# PIC32MX530F128H device description
Architecture: MIPS; Family: PIC32MX; Series: PIC32MX
Registers are 32-bit, read-write, no defined reset value unless marked. A register's access mark holds for its fields unless they carry their own. Offsets are from the block's base; [hi:lo] are bit positions; {n}, {i} and the like mark numbered series; 'fields as' and 'values as' point back to an identical list.

## FUSECONFIG
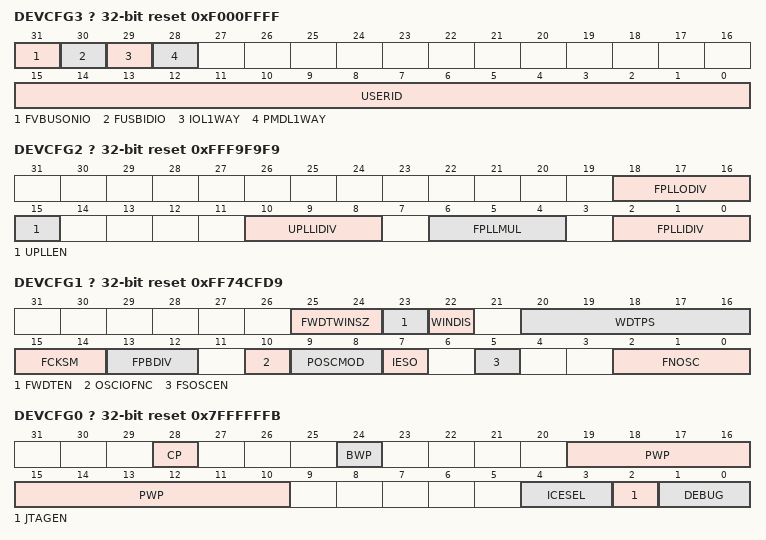
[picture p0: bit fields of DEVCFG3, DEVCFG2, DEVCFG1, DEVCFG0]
? DEVCFG3 size not given access not given reset 0xF000FFFF — Device Configuration Word 3
  [31] FVBUSONIO — USB VBUS_ON Selection bit
    1=ON (VBUSON pin is controlled by the USB module); 0=OFF (VBUSON pin is controlled by the port function)
  [30] FUSBIDIO — USB USBID Selection bit
    1=ON (USBID pin is controlled by the USB module); 0=OFF (USBID pin is controlled by the port function)
  [29] IOL1WAY — Peripheral Pin Select Configuration bit
    1=ON (Allow only one reconfiguration); 0=OFF (Allow multiple reconfigurations)
  [28] PMDL1WAY — Peripheral Module Disable Configuration bit
    values as IOL1WAY
  [15:0] USERID
    ?=User ID
? DEVCFG2 size not given access not given reset 0xFFF9F9F9 — Device Configuration Word 2
  [18:16] FPLLODIV — Default PLL Output Divisor bits
    7=DIV_256 (256x divider); 6=DIV_64 (64x divider); 5=DIV_32 (32x divider); 4=DIV_16 (16x divider); 3=DIV_8 (8x divider); 2=DIV_4 (4x divider); 1=DIV_2 (2x divider); 0=DIV_1 (1x divider)
  [15] UPLLEN — USB PLL Enable bit
    1=OFF (Disable and bypass USB PLL); 0=ON (Enable USB PLL)
  [10:8] UPLLIDIV — USB PLL Input Divider bits
    7=DIV_12 (12x divider); 6=DIV_10 (10x divider); {v}=DIV_{v+1} ({v+1}x divider) (v=0..5)
  [6:4] FPLLMUL — PLL Multiplier bits
    7=MUL_24 (24x multiplier); {v}=MUL_{v+15} ({v+15}x multiplier) (v=0..6)
  [2:0] FPLLIDIV — PLL Input Divider bits
    values as UPLLIDIV
? DEVCFG1 size not given access not given reset 0xFF74CFD9 — Device Configuration Word 1
  [25:24] FWDTWINSZ — Watchdog Timer Window Size bits
    3=WINSZ_25 (Window size is 25%); 2=WINSZ_37 (Window size is 37.5%); 1=WINSZ_50 (Window size is 50%); 0=WINSZ_75 (Window size is 75%)
  [23] FWDTEN — Watchdog Timer Enable bit
    0=OFF (Watchdog Timer is not enabled; it can be enabled in software); 1=ON (Watchdog Timer is enabled and cannot be disabled by software)
  [22] WINDIS — Watchdog Timer Window Enable bit
    1=OFF (Watchdog Timer is in non-Window mode); 0=ON (Watchdog Timer is in Window mode)
  [20:16] WDTPS — Watchdog Timer Postscale Select bits
    20=PS1048576 (1:1048576); 19=PS524288 (1:524288); 18=PS262144 (1:262144); 17=PS131072 (1:131072); 16=PS65536 (1:65536); 15=PS32768 (1:32768); 14=PS16384 (1:16384); 13=PS8192 (1:8192); 12=PS4096 (1:4096); 11=PS2048 (1:2048); 10=PS1024 (1:1024); 9=PS512 (1:512); 8=PS256 (1:256); 7=PS128 (1:128); 6=PS64 (1:64); 5=PS32 (1:32); 4=PS16 (1:16); 3=PS8 (1:8); 2=PS4 (1:4); 1=PS2 (1:2); 0=PS1 (1:1)
  [15:14] FCKSM — Clock Switching and Monitor Selection Configuration bits
    3=CSDCMD (Clock switching is disabled, Fail-Safe Clock Monitor is disabled); 1=CSECMD (Clock switching is enabled, Fail-Safe Clock Monitor is disabled); 0=CSECME (Clock switching is enabled, Fail-Safe Clock Monitor is enabled)
  [13:12] FPBDIV — Peripheral Bus Clock Divisor Default Value bits
    3=DIV_8 (PBCLK is SYSCLK divided by 8); 2=DIV_4 (PBCLK is SYSCLK divided by 4); 1=DIV_2 (PBCLK is SYSCLK divided by 2); 0=DIV_1 (PBCLK is SYSCLK divided by 1)
  [10] OSCIOFNC — CLKO Enable Configuration bit
    1=OFF (CLKO output is disabled); 0=ON (CLKO output signal active on the OSCO pin)
  [9:8] POSCMOD — Primary Oscillator Configuration bits
    3=OFF (Primary Oscillator disabled); 2=HS (HS Oscillator mode selected); 1=XT (XT Oscillator mode selected); 0=EC (External Clock mode selected)
  [7] IESO — Internal External Switchover bit
    0=OFF (Internal External Switchover mode is disabled (Two-Speed Start-up is disabled)); 1=ON (Internal External Switchover mode is enabled (Two-Speed Start-up is enabled))
  [5] FSOSCEN — Secondary Oscillator Enable bit
    0=OFF (Disable Secondary Oscillator); 1=ON (Enable Secondary Oscillator)
  [2:0] FNOSC — Oscillator Selection bits
    7=FRCDIV (Fast RC Oscillator with divide-by-N (FRCDIV)); 6=FRCDIV16 (FRCDIV16 Fast RC Oscillator with fixed divide-by-16 postscaler); 5=LPRC (Low-Power RC Oscillator (LPRC)); 4=SOSC (Secondary Oscillator (SOSC)); 3=PRIPLL (Primary Oscillator (POSC) with PLL module (XT+PLL, HS+PLL, EC+PLL)); 2=PRI (Primary Oscillator (XT, HS, EC)); 1=FRCPLL (Fast RC Oscillator with divide-by-N with PLL module (FRCDIV+PLL)); 0=FRC (Fast RC Oscillator (FRC))
? DEVCFG0 size not given access not given reset 0x7FFFFFFB — Device Configuration Word 0
  [28] CP — Code-Protect bit
    0=ON (Protection is enabled); 1=OFF (Protection is disabled)
  [24] BWP — Boot Flash Write-Protect bit
    1=OFF (Boot Flash is writable); 0=ON (Boot Flash is not writable)
  [19:10] PWP — Program Flash Write-Protect bits
    0x3ff=OFF (Disabled); 0x3fe=PWP1K (Memory below 0x400 address is write-protected); 0x3fd=PWP2K (Memory below 0x800 address is write-protected); 0x3fc=PWP3K (Memory below 0xC00 address is write-protected); 0x3fb=PWP4K (Memory below 0x1000 address is write-protected); 0x3fa=PWP5K (Memory below 0x1400 address is write-protected); 0x3f9=PWP6K (Memory below 0x1800 address is write-protected); 0x3f8=PWP7K (Memory below 0x1C00 address is write-protected); 0x3f7=PWP8K (Memory below 0x2000 address is write-protected); 0x3f6=PWP9K (Memory below 0x2400 address is write-protected); 0x3f5=PWP10K (Memory below 0x2800 address is write-protected); 0x3f4=PWP11K (Memory below 0x2C00 address is write-protected); 0x3f3=PWP12K (Memory below 0x3000 address is write-protected); 0x3f2=PWP13K (Memory below 0x3400 address is write-protected); 0x3f1=PWP14K (Memory below 0x3800 address is write-protected); 0x3f0=PWP15K (Memory below 0x3C00 address is write-protected); 0x3ef=PWP16K (Memory below 0x4000 address is write-protected); 0x3ee=PWP17K (Memory below 0x4400 address is write-protected); 0x3ed=PWP18K (Memory below 0x4800 address is write-protected); 0x3ec=PWP19K (Memory below 0x4C00 address is write-protected); 0x3eb=PWP20K (Memory below 0x5000 address is write-protected); 0x3ea=PWP21K (Memory below 0x5400 address is write-protected); 0x3e9=PWP22K (Memory below 0x5800 address is write-protected); 0x3e8=PWP23K (Memory below 0x5C00 address is write-protected); 0x3e7=PWP24K (Memory below 0x6000 address is write-protected); 0x3e6=PWP25K (Memory below 0x6400 address is write-protected); 0x3e5=PWP26K (Memory below 0x6800 address is write-protected); 0x3e4=PWP27K (Memory below 0x6C00 address is write-protected); 0x3e3=PWP28K (Memory below 0x7000 address is write-protected); 0x3e2=PWP29K (Memory below 0x7400 address is write-protected); 0x3e1=PWP30K (Memory below 0x7800 address is write-protected); 0x3e0=PWP31K (Memory below 0x7C00 address is write-protected); 0x3df=PWP32K (Memory below 0x8000 address is write-protected); 0x3de=PWP33K (Memory below 0x8400 address is write-protected); 0x3dd=PWP34K (Memory below 0x8800 address is write-protected); 0x3dc=PWP35K (Memory below 0x8C00 address is write-protected); 0x3db=PWP36K (Memory below 0x9000 address is write-protected); 0x3da=PWP37K (Memory below 0x9400 address is write-protected); 0x3d9=PWP38K (Memory below 0x9800 address is write-protected); 0x3d8=PWP39K (Memory below 0x9C00 address is write-protected); 0x3d7=PWP40K (Memory below 0xA000 address is write-protected); 0x3d6=PWP41K (Memory below 0xA400 address is write-protected); 0x3d5=PWP42K (Memory below 0xA800 address is write-protected); 0x3d4=PWP43K (Memory below 0xAC00 address is write-protected); 0x3d3=PWP44K (Memory below 0xB000 address is write-protected); 0x3d2=PWP45K (Memory below 0xB400 address is write-protected); 0x3d1=PWP46K (Memory below 0xB800 address is write-protected); 0x3d0=PWP47K (Memory below 0xBC00 address is write-protected); 0x3cf=PWP48K (Memory below 0xC000 address is write-protected); 0x3ce=PWP49K (Memory below 0xC400 address is write-protected); 0x3cd=PWP50K (Memory below 0xC800 address is write-protected); 0x3cc=PWP51K (Memory below 0xCC00 address is write-protected); 0x3cb=PWP52K (Memory below 0xD000 address is write-protected); 0x3ca=PWP53K (Memory below 0xD400 address is write-protected); 0x3c9=PWP54K (Memory below 0xD800 address is write-protected); 0x3c8=PWP55K (Memory below 0xDC00 address is write-protected); 0x3c7=PWP56K (Memory below 0xE000 address is write-protected); 0x3c6=PWP57K (Memory below 0xE400 address is write-protected); 0x3c5=PWP58K (Memory below 0xE800 address is write-protected); 0x3c4=PWP59K (Memory below 0xEC00 address is write-protected); 0x3c3=PWP60K (Memory below 0xF000 address is write-protected); 0x3c2=PWP61K (Memory below 0xF400 address is write-protected); 0x3c1=PWP62K (Memory below 0xF800 address is write-protected); 0x3c0=PWP63K (Memory below 0xFC00 address is write-protected); 0x3bf=PWP64K (Memory below 0x10000 address is write-protected); 0x3be=PWP65K (Memory below 0x10400 address is write-protected); 0x3bd=PWP66K (Memory below 0x10800 address is write-protected); 0x3bc=PWP67K (Memory below 0x10C00 address is write-protected); 0x3bb=PWP68K (Memory below 0x11000 address is write-protected); 0x3ba=PWP69K (Memory below 0x11400 address is write-protected); 0x3b9=PWP70K (Memory below 0x11800 address is write-protected); 0x3b8=PWP71K (Memory below 0x11C00 address is write-protected); 0x3b7=PWP72K (Memory below 0x12000 address is write-protected); 0x3b6=PWP73K (Memory below 0x12400 address is write-protected); 0x3b5=PWP74K (Memory below 0x12800 address is write-protected); 0x3b4=PWP75K (Memory below 0x12C00 address is write-protected); 0x3b3=PWP76K (Memory below 0x13000 address is write-protected); 0x3b2=PWP77K (Memory below 0x13400 address is write-protected); 0x3b1=PWP78K (Memory below 0x13800 address is write-protected); 0x3b0=PWP79K (Memory below 0x13C00 address is write-protected); 0x3af=PWP80K (Memory below 0x14000 address is write-protected); 0x3ae=PWP81K (Memory below 0x14400 address is write-protected); 0x3ad=PWP82K (Memory below 0x14800 address is write-protected); 0x3ac=PWP83K (Memory below 0x14C00 address is write-protected); 0x3ab=PWP84K (Memory below 0x15000 address is write-protected); 0x3aa=PWP85K (Memory below 0x15400 address is write-protected); 0x3a9=PWP86K (Memory below 0x15800 address is write-protected); 0x3a8=PWP87K (Memory below 0x15C00 address is write-protected); 0x3a7=PWP88K (Memory below 0x16000 address is write-protected); 0x3a6=PWP89K (Memory below 0x16400 address is write-protected); 0x3a5=PWP90K (Memory below 0x16800 address is write-protected); 0x3a4=PWP91K (Memory below 0x16C00 address is write-protected); 0x3a3=PWP92K (Memory below 0x17000 address is write-protected); 0x3a2=PWP93K (Memory below 0x17400 address is write-protected); 0x3a1=PWP94K (Memory below 0x17800 address is write-protected); 0x3a0=PWP95K (Memory below 0x17C00 address is write-protected); 0x39f=PWP96K (Memory below 0x18000 address is write-protected); 0x39e=PWP97K (Memory below 0x18400 address is write-protected); 0x39d=PWP98K (Memory below 0x18800 address is write-protected); 0x39c=PWP99K (Memory below 0x18C00 address is write-protected); 0x39b=PWP100K (Memory below 0x19000 address is write-protected); 0x39a=PWP101K (Memory below 0x19400 address is write-protected); 0x399=PWP102K (Memory below 0x19800 address is write-protected); 0x398=PWP103K (Memory below 0x19C00 address is write-protected); 0x397=PWP104K (Memory below 0x1A000 address is write-protected); 0x396=PWP105K (Memory below 0x1A400 address is write-protected); 0x395=PWP106K (Memory below 0x1A800 address is write-protected); 0x394=PWP107K (Memory below 0x1AC00 address is write-protected); 0x393=PWP108K (Memory below 0x1B000 address is write-protected); 0x392=PWP109K (Memory below 0x1B400 address is write-protected); 0x391=PWP110K (Memory below 0x1B800 address is write-protected); 0x390=PWP111K (Memory below 0x1BC00 address is write-protected); 0x38f=PWP112K (Memory below 0x1C000 address is write-protected); 0x38e=PWP113K (Memory below 0x1C400 address is write-protected); 0x38d=PWP114K (Memory below 0x1C800 address is write-protected); 0x38c=PWP115K (Memory below 0x1CC00 address is write-protected); 0x38b=PWP116K (Memory below 0x1D000 address is write-protected); 0x38a=PWP117K (Memory below 0x1D400 address is write-protected); 0x389=PWP118K (Memory below 0x1D800 address is write-protected); 0x388=PWP119K (Memory below 0x1DC00 address is write-protected); 0x387=PWP120K (Memory below 0x1E000 address is write-protected); 0x386=PWP121K (Memory below 0x1E400 address is write-protected); 0x385=PWP122K (Memory below 0x1E800 address is write-protected); 0x384=PWP123K (Memory below 0x1EC00 address is write-protected); 0x383=PWP124K (Memory below 0x1F000 address is write-protected); 0x382=PWP125K (Memory below 0x1F400 address is write-protected); 0x381=PWP126K (Memory below 0x1F800 address is write-protected); 0x380=PWP127K (Memory below 0x1FC00 address is write-protected); 0x37f=PWP128K (Memory below 0x20000 address is write-protected); 0x37e=PWP129K (Memory below 0x20400 address is write-protected); 0x37d=PWP130K (Memory below 0x20800 address is write-protected); 0x37c=PWP131K (Memory below 0x20C00 address is write-protected); 0x37b=PWP132K (Memory below 0x21000 address is write-protected); 0x37a=PWP133K (Memory below 0x21400 address is write-protected); 0x379=PWP134K (Memory below 0x21800 address is write-protected); 0x378=PWP135K (Memory below 0x21C00 address is write-protected); 0x377=PWP136K (Memory below 0x22000 address is write-protected); 0x376=PWP137K (Memory below 0x22400 address is write-protected); 0x375=PWP138K (Memory below 0x22800 address is write-protected); 0x374=PWP139K (Memory below 0x22C00 address is write-protected); 0x373=PWP140K (Memory below 0x23000 address is write-protected); 0x372=PWP141K (Memory below 0x23400 address is write-protected); 0x371=PWP142K (Memory below 0x23800 address is write-protected); 0x370=PWP143K (Memory below 0x23C00 address is write-protected); 0x36f=PWP144K (Memory below 0x24000 address is write-protected); 0x36e=PWP145K (Memory below 0x24400 address is write-protected); 0x36d=PWP146K (Memory below 0x24800 address is write-protected); 0x36c=PWP147K (Memory below 0x24C00 address is write-protected); 0x36b=PWP148K (Memory below 0x25000 address is write-protected); 0x36a=PWP149K (Memory below 0x25400 address is write-protected); 0x369=PWP150K (Memory below 0x25800 address is write-protected); 0x368=PWP151K (Memory below 0x25C00 address is write-protected); 0x367=PWP152K (Memory below 0x26000 address is write-protected); 0x366=PWP153K (Memory below 0x26400 address is write-protected); 0x365=PWP154K (Memory below 0x26800 address is write-protected); 0x364=PWP155K (Memory below 0x26C00 address is write-protected); 0x363=PWP156K (Memory below 0x27000 address is write-protected); 0x362=PWP157K (Memory below 0x27400 address is write-protected); 0x361=PWP158K (Memory below 0x27800 address is write-protected); 0x360=PWP159K (Memory below 0x27C00 address is write-protected); 0x35f=PWP160K (Memory below 0x28000 address is write-protected); 0x35e=PWP161K (Memory below 0x28400 address is write-protected); 0x35d=PWP162K (Memory below 0x28800 address is write-protected); 0x35c=PWP163K (Memory below 0x28C00 address is write-protected); 0x35b=PWP164K (Memory below 0x29000 address is write-protected); 0x35a=PWP165K (Memory below 0x29400 address is write-protected); 0x359=PWP166K (Memory below 0x29800 address is write-protected); 0x358=PWP167K (Memory below 0x29C00 address is write-protected); 0x357=PWP168K (Memory below 0x2A000 address is write-protected); 0x356=PWP169K (Memory below 0x2A400 address is write-protected); 0x355=PWP170K (Memory below 0x2A800 address is write-protected); 0x354=PWP171K (Memory below 0x2AC00 address is write-protected); 0x353=PWP172K (Memory below 0x2B000 address is write-protected); 0x352=PWP173K (Memory below 0x2B400 address is write-protected); 0x351=PWP174K (Memory below 0x2B800 address is write-protected); 0x350=PWP175K (Memory below 0x2BC00 address is write-protected); 0x34f=PWP176K (Memory below 0x2C000 address is write-protected); 0x34e=PWP177K (Memory below 0x2C400 address is write-protected); 0x34d=PWP178K (Memory below 0x2C800 address is write-protected); 0x34c=PWP179K (Memory below 0x2CC00 address is write-protected); 0x34b=PWP180K (Memory below 0x2D000 address is write-protected); 0x34a=PWP181K (Memory below 0x2D400 address is write-protected); 0x349=PWP182K (Memory below 0x2D800 address is write-protected); 0x348=PWP183K (Memory below 0x2DC00 address is write-protected); 0x347=PWP184K (Memory below 0x2E000 address is write-protected); 0x346=PWP185K (Memory below 0x2E400 address is write-protected); 0x345=PWP186K (Memory below 0x2E800 address is write-protected); 0x344=PWP187K (Memory below 0x2EC00 address is write-protected); 0x343=PWP188K (Memory below 0x2F000 address is write-protected); 0x342=PWP189K (Memory below 0x2F400 address is write-protected); 0x341=PWP190K (Memory below 0x2F800 address is write-protected); 0x340=PWP191K (Memory below 0x2FC00 address is write-protected); 0x33f=PWP192K (Memory below 0x30000 address is write-protected); 0x33e=PWP193K (Memory below 0x30400 address is write-protected); 0x33d=PWP194K (Memory below 0x30800 address is write-protected); 0x33c=PWP195K (Memory below 0x30C00 address is write-protected); 0x33b=PWP196K (Memory below 0x31000 address is write-protected); 0x33a=PWP197K (Memory below 0x31400 address is write-protected); 0x339=PWP198K (Memory below 0x31800 address is write-protected); 0x338=PWP199K (Memory below 0x31C00 address is write-protected); 0x337=PWP200K (Memory below 0x32000 address is write-protected); 0x336=PWP201K (Memory below 0x32400 address is write-protected); 0x335=PWP202K (Memory below 0x32800 address is write-protected); 0x334=PWP203K (Memory below 0x32C00 address is write-protected); 0x333=PWP204K (Memory below 0x33000 address is write-protected); 0x332=PWP205K (Memory below 0x33400 address is write-protected); 0x331=PWP206K (Memory below 0x33800 address is write-protected); 0x330=PWP207K (Memory below 0x33C00 address is write-protected); 0x32f=PWP208K (Memory below 0x34000 address is write-protected); 0x32e=PWP209K (Memory below 0x34400 address is write-protected); 0x32d=PWP210K (Memory below 0x34800 address is write-protected); 0x32c=PWP211K (Memory below 0x34C00 address is write-protected); 0x32b=PWP212K (Memory below 0x35000 address is write-protected); 0x32a=PWP213K (Memory below 0x35400 address is write-protected); 0x329=PWP214K (Memory below 0x35800 address is write-protected); 0x328=PWP215K (Memory below 0x35C00 address is write-protected); 0x327=PWP216K (Memory below 0x36000 address is write-protected); 0x326=PWP217K (Memory below 0x36400 address is write-protected); 0x325=PWP218K (Memory below 0x36800 address is write-protected); 0x324=PWP219K (Memory below 0x36C00 address is write-protected); 0x323=PWP220K (Memory below 0x37000 address is write-protected); 0x322=PWP221K (Memory below 0x37400 address is write-protected); 0x321=PWP222K (Memory below 0x37800 address is write-protected); 0x320=PWP223K (Memory below 0x37C00 address is write-protected); 0x31f=PWP224K (Memory below 0x38000 address is write-protected); 0x31e=PWP225K (Memory below 0x38400 address is write-protected); 0x31d=PWP226K (Memory below 0x38800 address is write-protected); 0x31c=PWP227K (Memory below 0x38C00 address is write-protected); 0x31b=PWP228K (Memory below 0x39000 address is write-protected); 0x31a=PWP229K (Memory below 0x39400 address is write-protected); 0x319=PWP230K (Memory below 0x39800 address is write-protected); 0x318=PWP231K (Memory below 0x39C00 address is write-protected); 0x317=PWP232K (Memory below 0x3A000 address is write-protected); 0x316=PWP233K (Memory below 0x3A400 address is write-protected); 0x315=PWP234K (Memory below 0x3A800 address is write-protected); 0x314=PWP235K (Memory below 0x3AC00 address is write-protected); 0x313=PWP236K (Memory below 0x3B000 address is write-protected); 0x312=PWP237K (Memory below 0x3B400 address is write-protected); 0x311=PWP238K (Memory below 0x3B800 address is write-protected); 0x310=PWP239K (Memory below 0x3BC00 address is write-protected); 0x30f=PWP240K (Memory below 0x3C000 address is write-protected); 0x30e=PWP241K (Memory below 0x3C400 address is write-protected); 0x30d=PWP242K (Memory below 0x3C800 address is write-protected); 0x30c=PWP243K (Memory below 0x3CC00 address is write-protected); 0x30b=PWP244K (Memory below 0x3D000 address is write-protected); 0x30a=PWP245K (Memory below 0x3D400 address is write-protected); 0x309=PWP246K (Memory below 0x3D800 address is write-protected); 0x308=PWP247K (Memory below 0x3DC00 address is write-protected); 0x307=PWP248K (Memory below 0x3E000 address is write-protected); 0x306=PWP249K (Memory below 0x3E400 address is write-protected); 0x305=PWP250K (Memory below 0x3E800 address is write-protected); 0x304=PWP251K (Memory below 0x3EC00 address is write-protected); 0x303=PWP252K (Memory below 0x3F000 address is write-protected); 0x302=PWP253K (Memory below 0x3F400 address is write-protected); 0x301=PWP254K (Memory below 0x3F800 address is write-protected); 0x300=PWP255K (Memory below 0x3FC00 address is write-protected); 0x2ff=PWP256K (Memory below 0x40000 address is write-protected); 0x2fe=PWP257K (Memory below 0x40400 address is write-protected); 0x2fd=PWP258K (Memory below 0x40800 address is write-protected); 0x2fc=PWP259K (Memory below 0x40C00 address is write-protected); 0x2fb=PWP260K (Memory below 0x41000 address is write-protected); 0x2fa=PWP261K (Memory below 0x41400 address is write-protected); 0x2f9=PWP262K (Memory below 0x41800 address is write-protected); 0x2f8=PWP263K (Memory below 0x41C00 address is write-protected); 0x2f7=PWP264K (Memory below 0x42000 address is write-protected); 0x2f6=PWP265K (Memory below 0x42400 address is write-protected); 0x2f5=PWP266K (Memory below 0x42800 address is write-protected); 0x2f4=PWP267K (Memory below 0x42C00 address is write-protected); 0x2f3=PWP268K (Memory below 0x43000 address is write-protected); 0x2f2=PWP269K (Memory below 0x43400 address is write-protected); 0x2f1=PWP270K (Memory below 0x43800 address is write-protected); 0x2f0=PWP271K (Memory below 0x43C00 address is write-protected); 0x2ef=PWP272K (Memory below 0x44000 address is write-protected); 0x2ee=PWP273K (Memory below 0x44400 address is write-protected); 0x2ed=PWP274K (Memory below 0x44800 address is write-protected); 0x2ec=PWP275K (Memory below 0x44C00 address is write-protected); 0x2eb=PWP276K (Memory below 0x45000 address is write-protected); 0x2ea=PWP277K (Memory below 0x45400 address is write-protected); 0x2e9=PWP278K (Memory below 0x45800 address is write-protected); 0x2e8=PWP279K (Memory below 0x45C00 address is write-protected); 0x2e7=PWP280K (Memory below 0x46000 address is write-protected); 0x2e6=PWP281K (Memory below 0x46400 address is write-protected); 0x2e5=PWP282K (Memory below 0x46800 address is write-protected); 0x2e4=PWP283K (Memory below 0x46C00 address is write-protected); 0x2e3=PWP284K (Memory below 0x47000 address is write-protected); 0x2e2=PWP285K (Memory below 0x47400 address is write-protected); 0x2e1=PWP286K (Memory below 0x47800 address is write-protected); 0x2e0=PWP287K (Memory below 0x47C00 address is write-protected); 0x2df=PWP288K (Memory below 0x48000 address is write-protected); 0x2de=PWP289K (Memory below 0x48400 address is write-protected); 0x2dd=PWP290K (Memory below 0x48800 address is write-protected); 0x2dc=PWP291K (Memory below 0x48C00 address is write-protected); 0x2db=PWP292K (Memory below 0x49000 address is write-protected); 0x2da=PWP293K (Memory below 0x49400 address is write-protected); 0x2d9=PWP294K (Memory below 0x49800 address is write-protected); 0x2d8=PWP295K (Memory below 0x49C00 address is write-protected); 0x2d7=PWP296K (Memory below 0x4A000 address is write-protected); 0x2d6=PWP297K (Memory below 0x4A400 address is write-protected); 0x2d5=PWP298K (Memory below 0x4A800 address is write-protected); 0x2d4=PWP299K (Memory below 0x4AC00 address is write-protected); 0x2d3=PWP300K (Memory below 0x4B000 address is write-protected); 0x2d2=PWP301K (Memory below 0x4B400 address is write-protected); 0x2d1=PWP302K (Memory below 0x4B800 address is write-protected); 0x2d0=PWP303K (Memory below 0x4BC00 address is write-protected); 0x2cf=PWP304K (Memory below 0x4C000 address is write-protected); 0x2ce=PWP305K (Memory below 0x4C400 address is write-protected); 0x2cd=PWP306K (Memory below 0x4C800 address is write-protected); 0x2cc=PWP307K (Memory below 0x4CC00 address is write-protected); 0x2cb=PWP308K (Memory below 0x4D000 address is write-protected); 0x2ca=PWP309K (Memory below 0x4D400 address is write-protected); 0x2c9=PWP310K (Memory below 0x4D800 address is write-protected); 0x2c8=PWP311K (Memory below 0x4DC00 address is write-protected); 0x2c7=PWP312K (Memory below 0x4E000 address is write-protected); 0x2c6=PWP313K (Memory below 0x4E400 address is write-protected); 0x2c5=PWP314K (Memory below 0x4E800 address is write-protected); 0x2c4=PWP315K (Memory below 0x4EC00 address is write-protected); 0x2c3=PWP316K (Memory below 0x4F000 address is write-protected); 0x2c2=PWP317K (Memory below 0x4F400 address is write-protected); 0x2c1=PWP318K (Memory below 0x4F800 address is write-protected); 0x2c0=PWP319K (Memory below 0x4FC00 address is write-protected); 0x2bf=PWP320K (Memory below 0x50000 address is write-protected); 0x2be=PWP321K (Memory below 0x50400 address is write-protected); 0x2bd=PWP322K (Memory below 0x50800 address is write-protected); 0x2bc=PWP323K (Memory below 0x50C00 address is write-protected); 0x2bb=PWP324K (Memory below 0x51000 address is write-protected); 0x2ba=PWP325K (Memory below 0x51400 address is write-protected); 0x2b9=PWP326K (Memory below 0x51800 address is write-protected); 0x2b8=PWP327K (Memory below 0x51C00 address is write-protected); 0x2b7=PWP328K (Memory below 0x52000 address is write-protected); 0x2b6=PWP329K (Memory below 0x52400 address is write-protected); 0x2b5=PWP330K (Memory below 0x52800 address is write-protected); 0x2b4=PWP331K (Memory below 0x52C00 address is write-protected); 0x2b3=PWP332K (Memory below 0x53000 address is write-protected); 0x2b2=PWP333K (Memory below 0x53400 address is write-protected); 0x2b1=PWP334K (Memory below 0x53800 address is write-protected); 0x2b0=PWP335K (Memory below 0x53C00 address is write-protected); 0x2af=PWP336K (Memory below 0x54000 address is write-protected); 0x2ae=PWP337K (Memory below 0x54400 address is write-protected); 0x2ad=PWP338K (Memory below 0x54800 address is write-protected); 0x2ac=PWP339K (Memory below 0x54C00 address is write-protected); 0x2ab=PWP340K (Memory below 0x55000 address is write-protected); 0x2aa=PWP341K (Memory below 0x55400 address is write-protected); 0x2a9=PWP342K (Memory below 0x55800 address is write-protected); 0x2a8=PWP343K (Memory below 0x55C00 address is write-protected); 0x2a7=PWP344K (Memory below 0x56000 address is write-protected); 0x2a6=PWP345K (Memory below 0x56400 address is write-protected); 0x2a5=PWP346K (Memory below 0x56800 address is write-protected); 0x2a4=PWP347K (Memory below 0x56C00 address is write-protected); 0x2a3=PWP348K (Memory below 0x57000 address is write-protected); 0x2a2=PWP349K (Memory below 0x57400 address is write-protected); 0x2a1=PWP350K (Memory below 0x57800 address is write-protected); 0x2a0=PWP351K (Memory below 0x57C00 address is write-protected); 0x29f=PWP352K (Memory below 0x58000 address is write-protected); 0x29e=PWP353K (Memory below 0x58400 address is write-protected); 0x29d=PWP354K (Memory below 0x58800 address is write-protected); 0x29c=PWP355K (Memory below 0x58C00 address is write-protected); 0x29b=PWP356K (Memory below 0x59000 address is write-protected); 0x29a=PWP357K (Memory below 0x59400 address is write-protected); 0x299=PWP358K (Memory below 0x59800 address is write-protected); 0x298=PWP359K (Memory below 0x59C00 address is write-protected); 0x297=PWP360K (Memory below 0x5A000 address is write-protected); 0x296=PWP361K (Memory below 0x5A400 address is write-protected); 0x295=PWP362K (Memory below 0x5A800 address is write-protected); 0x294=PWP363K (Memory below 0x5AC00 address is write-protected); 0x293=PWP364K (Memory below 0x5B000 address is write-protected); 0x292=PWP365K (Memory below 0x5B400 address is write-protected); 0x291=PWP366K (Memory below 0x5B800 address is write-protected); 0x290=PWP367K (Memory below 0x5BC00 address is write-protected); 0x28f=PWP368K (Memory below 0x5C000 address is write-protected); 0x28e=PWP369K (Memory below 0x5C400 address is write-protected); 0x28d=PWP370K (Memory below 0x5C800 address is write-protected); 0x28c=PWP371K (Memory below 0x5CC00 address is write-protected); 0x28b=PWP372K (Memory below 0x5D000 address is write-protected); 0x28a=PWP373K (Memory below 0x5D400 address is write-protected); 0x289=PWP374K (Memory below 0x5D800 address is write-protected); 0x288=PWP375K (Memory below 0x5DC00 address is write-protected); 0x287=PWP376K (Memory below 0x5E000 address is write-protected); 0x286=PWP377K (Memory below 0x5E400 address is write-protected); 0x285=PWP378K (Memory below 0x5E800 address is write-protected); 0x284=PWP379K (Memory below 0x5EC00 address is write-protected); 0x283=PWP380K (Memory below 0x5F000 address is write-protected); 0x282=PWP381K (Memory below 0x5F400 address is write-protected); 0x281=PWP382K (Memory below 0x5F800 address is write-protected); 0x280=PWP383K (Memory below 0x5FC00 address is write-protected); 0x27f=PWP384K (Memory below 0x60000 address is write-protected); 0x27e=PWP385K (Memory below 0x60400 address is write-protected); 0x27d=PWP386K (Memory below 0x60800 address is write-protected); 0x27c=PWP387K (Memory below 0x60C00 address is write-protected); 0x27b=PWP388K (Memory below 0x61000 address is write-protected); 0x27a=PWP389K (Memory below 0x61400 address is write-protected); 0x279=PWP390K (Memory below 0x61800 address is write-protected); 0x278=PWP391K (Memory below 0x61C00 address is write-protected); 0x277=PWP392K (Memory below 0x62000 address is write-protected); 0x276=PWP393K (Memory below 0x62400 address is write-protected); 0x275=PWP394K (Memory below 0x62800 address is write-protected); 0x274=PWP395K (Memory below 0x62C00 address is write-protected); 0x273=PWP396K (Memory below 0x63000 address is write-protected); 0x272=PWP397K (Memory below 0x63400 address is write-protected); 0x271=PWP398K (Memory below 0x63800 address is write-protected); 0x270=PWP399K (Memory below 0x63C00 address is write-protected); 0x26f=PWP400K (Memory below 0x64000 address is write-protected); 0x26e=PWP401K (Memory below 0x64400 address is write-protected); 0x26d=PWP402K (Memory below 0x64800 address is write-protected); 0x26c=PWP403K (Memory below 0x64C00 address is write-protected); 0x26b=PWP404K (Memory below 0x65000 address is write-protected); 0x26a=PWP405K (Memory below 0x65400 address is write-protected); 0x269=PWP406K (Memory below 0x65800 address is write-protected); 0x268=PWP407K (Memory below 0x65C00 address is write-protected); 0x267=PWP408K (Memory below 0x66000 address is write-protected); 0x266=PWP409K (Memory below 0x66400 address is write-protected); 0x265=PWP410K (Memory below 0x66800 address is write-protected); 0x264=PWP411K (Memory below 0x66C00 address is write-protected); 0x263=PWP412K (Memory below 0x67000 address is write-protected); 0x262=PWP413K (Memory below 0x67400 address is write-protected); 0x261=PWP414K (Memory below 0x67800 address is write-protected); 0x260=PWP415K (Memory below 0x67C00 address is write-protected); 0x25f=PWP416K (Memory below 0x68000 address is write-protected); 0x25e=PWP417K (Memory below 0x68400 address is write-protected); 0x25d=PWP418K (Memory below 0x68800 address is write-protected); 0x25c=PWP419K (Memory below 0x68C00 address is write-protected); 0x25b=PWP420K (Memory below 0x69000 address is write-protected); 0x25a=PWP421K (Memory below 0x69400 address is write-protected); 0x259=PWP422K (Memory below 0x69800 address is write-protected); 0x258=PWP423K (Memory below 0x69C00 address is write-protected); 0x257=PWP424K (Memory below 0x6A000 address is write-protected); 0x256=PWP425K (Memory below 0x6A400 address is write-protected); 0x255=PWP426K (Memory below 0x6A800 address is write-protected); 0x254=PWP427K (Memory below 0x6AC00 address is write-protected); 0x253=PWP428K (Memory below 0x6B000 address is write-protected); 0x252=PWP429K (Memory below 0x6B400 address is write-protected); 0x251=PWP430K (Memory below 0x6B800 address is write-protected); 0x250=PWP431K (Memory below 0x6BC00 address is write-protected); 0x24f=PWP432K (Memory below 0x6C000 address is write-protected); 0x24e=PWP433K (Memory below 0x6C400 address is write-protected); 0x24d=PWP434K (Memory below 0x6C800 address is write-protected); 0x24c=PWP435K (Memory below 0x6CC00 address is write-protected); 0x24b=PWP436K (Memory below 0x6D000 address is write-protected); 0x24a=PWP437K (Memory below 0x6D400 address is write-protected); 0x249=PWP438K (Memory below 0x6D800 address is write-protected); 0x248=PWP439K (Memory below 0x6DC00 address is write-protected); 0x247=PWP440K (Memory below 0x6E000 address is write-protected); 0x246=PWP441K (Memory below 0x6E400 address is write-protected); 0x245=PWP442K (Memory below 0x6E800 address is write-protected); 0x244=PWP443K (Memory below 0x6EC00 address is write-protected); 0x243=PWP444K (Memory below 0x6F000 address is write-protected); 0x242=PWP445K (Memory below 0x6F400 address is write-protected); 0x241=PWP446K (Memory below 0x6F800 address is write-protected); 0x240=PWP447K (Memory below 0x6FC00 address is write-protected); 0x23f=PWP448K (Memory below 0x70000 address is write-protected); 0x23e=PWP449K (Memory below 0x70400 address is write-protected); 0x23d=PWP450K (Memory below 0x70800 address is write-protected); 0x23c=PWP451K (Memory below 0x70C00 address is write-protected); 0x23b=PWP452K (Memory below 0x71000 address is write-protected); 0x23a=PWP453K (Memory below 0x71400 address is write-protected); 0x239=PWP454K (Memory below 0x71800 address is write-protected); 0x238=PWP455K (Memory below 0x71C00 address is write-protected); 0x237=PWP456K (Memory below 0x72000 address is write-protected); 0x236=PWP457K (Memory below 0x72400 address is write-protected); 0x235=PWP458K (Memory below 0x72800 address is write-protected); 0x234=PWP459K (Memory below 0x72C00 address is write-protected); 0x233=PWP460K (Memory below 0x73000 address is write-protected); 0x232=PWP461K (Memory below 0x73400 address is write-protected); 0x231=PWP462K (Memory below 0x73800 address is write-protected); 0x230=PWP463K (Memory below 0x73C00 address is write-protected); 0x22f=PWP464K (Memory below 0x74000 address is write-protected); 0x22e=PWP465K (Memory below 0x74400 address is write-protected); 0x22d=PWP466K (Memory below 0x74800 address is write-protected); 0x22c=PWP467K (Memory below 0x74C00 address is write-protected); 0x22b=PWP468K (Memory below 0x75000 address is write-protected); 0x22a=PWP469K (Memory below 0x75400 address is write-protected); 0x229=PWP470K (Memory below 0x75800 address is write-protected); 0x228=PWP471K (Memory below 0x75C00 address is write-protected); 0x227=PWP472K (Memory below 0x76000 address is write-protected); 0x226=PWP473K (Memory below 0x76400 address is write-protected); 0x225=PWP474K (Memory below 0x76800 address is write-protected); 0x224=PWP475K (Memory below 0x76C00 address is write-protected); 0x223=PWP476K (Memory below 0x77000 address is write-protected); 0x222=PWP477K (Memory below 0x77400 address is write-protected); 0x221=PWP478K (Memory below 0x77800 address is write-protected); 0x220=PWP479K (Memory below 0x77C00 address is write-protected); 0x21f=PWP480K (Memory below 0x78000 address is write-protected); 0x21e=PWP481K (Memory below 0x78400 address is write-protected); 0x21d=PWP482K (Memory below 0x78800 address is write-protected); 0x21c=PWP483K (Memory below 0x78C00 address is write-protected); 0x21b=PWP484K (Memory below 0x79000 address is write-protected); 0x21a=PWP485K (Memory below 0x79400 address is write-protected); 0x219=PWP486K (Memory below 0x79800 address is write-protected); 0x218=PWP487K (Memory below 0x79C00 address is write-protected); 0x217=PWP488K (Memory below 0x7A000 address is write-protected); 0x216=PWP489K (Memory below 0x7A400 address is write-protected); 0x215=PWP490K (Memory below 0x7A800 address is write-protected); 0x214=PWP491K (Memory below 0x7AC00 address is write-protected); 0x213=PWP492K (Memory below 0x7B000 address is write-protected); 0x212=PWP493K (Memory below 0x7B400 address is write-protected); 0x211=PWP494K (Memory below 0x7B800 address is write-protected); 0x210=PWP495K (Memory below 0x7BC00 address is write-protected); 0x20f=PWP496K (Memory below 0x7C000 address is write-protected); 0x20e=PWP497K (Memory below 0x7C400 address is write-protected); 0x20d=PWP498K (Memory below 0x7C800 address is write-protected); 0x20c=PWP499K (Memory below 0x7CC00 address is write-protected); 0x20b=PWP500K (Memory below 0x7D000 address is write-protected); 0x20a=PWP501K (Memory below 0x7D400 address is write-protected); 0x209=PWP502K (Memory below 0x7D800 address is write-protected); 0x208=PWP503K (Memory below 0x7DC00 address is write-protected); 0x207=PWP504K (Memory below 0x7E000 address is write-protected); 0x206=PWP505K (Memory below 0x7E400 address is write-protected); 0x205=PWP506K (Memory below 0x7E800 address is write-protected); 0x204=PWP507K (Memory below 0x7EC00 address is write-protected); 0x203=PWP508K (Memory below 0x7F000 address is write-protected); 0x202=PWP509K (Memory below 0x7F400 address is write-protected); 0x201=PWP510K (Memory below 0x7F800 address is write-protected); 0x200=PWP511K (Memory below 0x7FC00 address is write-protected); 0x1ff=PWP512K (Memory below 0x80000 address is write-protected)
  [4:3] ICESEL — In-Circuit Emulator/Debugger Communication Channel Select bits
    3=ICS_PGx1 (PGEC1/PGED1 pair is used); 2=ICS_PGx2 (PGEC2/PGED2 pair is used); 1=ICS_PGx3 (PGEC3/PGED3 pair is used)
  [2] JTAGEN — JTAG Enable bit
    1=ON (JTAG Port Enabled); 0=OFF (JTAG Disabled)
  [1:0] DEBUG — Background Debugger Enable bits
    0=OFF (Debugger is disabled); 3=ON (Debugger is enabled)

## Notices in the file
Copyright (c) 2019 Microchip Technology Inc.
SPDX-License-Identifier: Apache-2.0
Licensed under the Apache License, Version 2.0 (the "License");
you may not use this file except in compliance with the License.
You may obtain a copy of the License at
http://www.apache.org/licenses/LICENSE-2.0
Unless required by applicable law or agreed to in writing, software
distributed under the License is distributed on an "AS IS" BASIS,
WITHOUT WARRANTIES OR CONDITIONS OF ANY KIND, either express or implied.
See the License for the specific language governing permissions and
limitations under the License.
